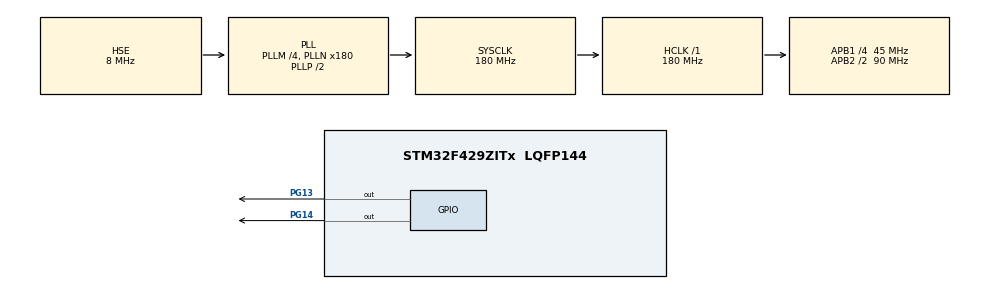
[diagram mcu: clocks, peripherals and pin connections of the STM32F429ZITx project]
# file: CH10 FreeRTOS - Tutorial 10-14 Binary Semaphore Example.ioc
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FREERTOS.Tasks01=defaultTask,24,128,StartDefaultTask,Default,NULL,Dynamic,NULL,NULL
FREERTOS.configUSE_NEWLIB_REENTRANT=1
Mcu.Family=STM32F4
Mcu.Name=STM32F429ZITx
Mcu.Package=LQFP144
NVIC.PriorityGroup=NVIC_PRIORITYGROUP_4
NVIC.TIM6_DAC_IRQn=true\:0\:0\:true\:false\:true\:false\:false\:true\:true
NVIC.TimeBase=TIM6_DAC_IRQn
NVIC.TimeBaseIP=TIM6
PG13.Signal=GPIO_Output
PG14.Signal=GPIO_Output
PH0/OSC_IN.Mode=HSE-External-Oscillator
PH0/OSC_IN.Signal=RCC_OSC_IN
PH1/OSC_OUT.Mode=HSE-External-Oscillator
PH1/OSC_OUT.Signal=RCC_OSC_OUT
ProjectManager.HeapSize=0x200
ProjectManager.StackSize=0x400
ProjectManager.TargetToolchain=STM32CubeIDE
RCC.48MHZClocksFreq_Value=51428571.428571425
RCC.AHBFreq_Value=180000000
RCC.APB1CLKDivider=RCC_HCLK_DIV4
RCC.APB1Freq_Value=45000000
RCC.APB1TimFreq_Value=90000000
RCC.APB2CLKDivider=RCC_HCLK_DIV2
RCC.APB2Freq_Value=90000000
RCC.APB2TimFreq_Value=180000000
RCC.CortexFreq_Value=180000000
RCC.HCLKFreq_Value=180000000
RCC.HSE_VALUE=8000000
RCC.HSI_VALUE=16000000
RCC.LSE_VALUE=32768
RCC.PLLM=4
RCC.PLLN=180
RCC.PLLQ=7
RCC.PLLSourceVirtual=RCC_PLLSOURCE_HSE
RCC.SYSCLKFreq_VALUE=180000000
RCC.SYSCLKSource=RCC_SYSCLKSOURCE_PLLCLK
RCC.VCOOutputFreq_Value=360000000
VP_FREERTOS_VS_CMSIS_V2.Mode=CMSIS_V2
VP_SYS_VS_tim6.Mode=TIM6
board=STM32F429I-DISC1

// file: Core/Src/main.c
/* USER CODE BEGIN Header */
/**
  ******************************************************************************
  * @file           : main.c
  * @brief          : Main program body
  ******************************************************************************
  * @attention
  *
  * Copyright (c) 2024 STMicroelectronics.
  * All rights reserved.
  *
  * This software is licensed under terms that can be found in the LICENSE file
  * in the root directory of this software component.
  * If no LICENSE file comes with this software, it is provided AS-IS.
  *
  ******************************************************************************
  */

	/***************************** Tutorial Tags ******************************
		 FreeRTOS
		 Binary semaphore
		 Task management (priority, state)
		 GPIO output
	 **************************************************************************/

	/* 10.5 Binary semaphore in FreeRTOS: **************************************
	 * Tutorial -10-14: The binary semaphore example in FreeRTOS
	 *
	WARNING: CODE is written mostly without help of CubeMX. If you regenerate code using CubeMX
	you will lose the code here.

    In this tutorial, we repeat the code in tutorial 10.13 now
	using a binary semaphore. When the code is executed, myTask02 is called first since
	it has higher priority. This task calls the function LEDChange and the green LED on
	the STM32F4 board is turned on. After one second, myTask2 yields for 0.5 s. Then,
	the default task is called. This task calls the function LEDChange and the green LED
	is turned off. After 0.5 s, myTask2 becomes ready and tries to preempt. However,
	the binary semaphore token has been acquired by the default task. Hence, myTask2
	waits for extra 0.5 s even if it has higher priority. myTask2 is executed again when
	the default task releases the binary semaphore token. As a result, green LED toggles
	every second.

	***************************************************************************/

/* USER CODE END Header */
#include "main.h"
#include "cmsis_os.h"

/* USER CODE BEGIN Includes */
#include "stdio.h"
/* USER CODE END Includes */

/* Definitions for defaultTask */
osThreadId_t defaultTaskHandle;
const osThreadAttr_t defaultTask_attributes = {
  .name = "defaultTask",
  .stack_size = 128 * 4,
  .priority = (osPriority_t) osPriorityNormal,
};

/*Definition for myTask02*/
/* USER CODE BEGIN PV */
osThreadId_t myTask02Handle;
const osThreadAttr_t myTask02_attributes = {
		.name = "myTask02",
		.stack_size = 128 * 4,
		.priority = (osPriority_t) osPriorityAboveNormal,
};

/*Definition for myTask02*/
osSemaphoreId_t myBinarySem01Handle;

const osSemaphoreAttr_t myBinarySem01_attributes = {
		.name = "myBinarySem01",
};

// LED GPIO PIN state
int condition;

/* USER CODE END PV */

void SystemClock_Config(void);
static void MX_GPIO_Init(void);

void StartDefaultTask(void *argument);
void StartmyTask02(void *argument);

/*Shared function*/
void ledChange(int condition);

/* USER CODE BEGIN 0 */
/*Function needed to use printf on CONSOLE*/
int _write(int file, char *ptr, int len){
	  int i = 0;
	  for (i=0; i<len; i++)
		  ITM_SendChar((*ptr++));
	  return len;
}
/* USER CODE END 0 */

int main(void)
{

  /* MCU Configuration--------------------------------------------------------*/

  /* Reset of all peripherals, Initializes the Flash interface and the Systick. */
  HAL_Init();

  /* Configure the system clock */
  SystemClock_Config();

  /* Initialize all configured peripherals */
  MX_GPIO_Init();
  /* USER CODE BEGIN 2 */
  printf("PROGRAM START \n\r");
  /* USER CODE END 2 */

  /* Init scheduler */
  osKernelInitialize();

  /* USER CODE BEGIN RTOS_SEMAPHORES */
  myBinarySem01Handle = osSemaphoreNew(1, 1, &myBinarySem01_attributes);
  /* USER CODE END RTOS_SEMAPHORES */

  /* Create the thread(s) */
  /* creation of defaultTask */
  defaultTaskHandle = osThreadNew(StartDefaultTask, NULL, &defaultTask_attributes);

  /* USER CODE BEGIN RTOS_THREADS */
  myTask02Handle = osThreadNew(StartmyTask02, NULL, &myTask02_attributes);
  /* USER CODE END RTOS_THREADS */

  /* Start scheduler */
  osKernelStart();

  /* We should never get here as control is now taken by the scheduler */
  /* Infinite loop */
  while (1)
  {

  }
}

void SystemClock_Config(void)
{
  RCC_OscInitTypeDef RCC_OscInitStruct = {0};
  RCC_ClkInitTypeDef RCC_ClkInitStruct = {0};

  /** Configure the main internal regulator output voltage
  */
  __HAL_RCC_PWR_CLK_ENABLE();
  __HAL_PWR_VOLTAGESCALING_CONFIG(PWR_REGULATOR_VOLTAGE_SCALE1);

  /** Initializes the RCC Oscillators according to the specified parameters
  * in the RCC_OscInitTypeDef structure.
  */
  RCC_OscInitStruct.OscillatorType = RCC_OSCILLATORTYPE_HSE;
  RCC_OscInitStruct.HSEState = RCC_HSE_ON;
  RCC_OscInitStruct.PLL.PLLState = RCC_PLL_ON;
  RCC_OscInitStruct.PLL.PLLSource = RCC_PLLSOURCE_HSE;
  RCC_OscInitStruct.PLL.PLLM = 4;
  RCC_OscInitStruct.PLL.PLLN = 180;
  RCC_OscInitStruct.PLL.PLLP = RCC_PLLP_DIV2;
  RCC_OscInitStruct.PLL.PLLQ = 7;
  if (HAL_RCC_OscConfig(&RCC_OscInitStruct) != HAL_OK)
  {
    Error_Handler();
  }

  /** Activate the Over-Drive mode
  */
  if (HAL_PWREx_EnableOverDrive() != HAL_OK)
  {
    Error_Handler();
  }

  /** Initializes the CPU, AHB and APB buses clocks
  */
  RCC_ClkInitStruct.ClockType = RCC_CLOCKTYPE_HCLK|RCC_CLOCKTYPE_SYSCLK
                              |RCC_CLOCKTYPE_PCLK1|RCC_CLOCKTYPE_PCLK2;
  RCC_ClkInitStruct.SYSCLKSource = RCC_SYSCLKSOURCE_PLLCLK;
  RCC_ClkInitStruct.AHBCLKDivider = RCC_SYSCLK_DIV1;
  RCC_ClkInitStruct.APB1CLKDivider = RCC_HCLK_DIV4;
  RCC_ClkInitStruct.APB2CLKDivider = RCC_HCLK_DIV2;

  if (HAL_RCC_ClockConfig(&RCC_ClkInitStruct, FLASH_LATENCY_5) != HAL_OK)
  {
    Error_Handler();
  }
}

static void MX_GPIO_Init(void)
{
  GPIO_InitTypeDef GPIO_InitStruct = {0};

  /* GPIO Ports Clock Enable */
  __HAL_RCC_GPIOH_CLK_ENABLE();
  __HAL_RCC_GPIOG_CLK_ENABLE();

  /*Configure GPIO pin Output Level */
  HAL_GPIO_WritePin(GPIOG, GPIO_PIN_13|GPIO_PIN_14, GPIO_PIN_RESET);

  /*Configure GPIO pins : PG13 PG14 */
  GPIO_InitStruct.Pin = GPIO_PIN_13|GPIO_PIN_14;
  GPIO_InitStruct.Mode = GPIO_MODE_OUTPUT_PP;
  GPIO_InitStruct.Pull = GPIO_NOPULL;
  GPIO_InitStruct.Speed = GPIO_SPEED_FREQ_LOW;
  HAL_GPIO_Init(GPIOG, &GPIO_InitStruct);

}

void StartDefaultTask(void *argument)
{
  /* USER CODE BEGIN 5 */

  /* Infinite loop */
  for(;;)
  {
	  printf("DefaultTask \n\r");
	  ledChange(0);
	  osThreadYield();
  }
  /* USER CODE END 5 */
}

void StartmyTask02(void *argument)
{
  /* USER CODE BEGIN 5 */

  /* Infinite loop */
  for(;;)
  {
	  printf("myTask02 \n");
	  ledChange(1);
	  osDelay(500);
  }
  /* USER CODE END 5 */
}

void ledChange(int condition){
	osSemaphoreAcquire(myBinarySem01Handle, osWaitForever);

	HAL_GPIO_WritePin(GPIOG, GPIO_PIN_13, condition);
	HAL_Delay(1000);

	osSemaphoreRelease(myBinarySem01Handle);
}

void HAL_TIM_PeriodElapsedCallback(TIM_HandleTypeDef *htim)
{
  if (htim->Instance == TIM6) {
    HAL_IncTick();
  }
}

void Error_Handler(void)
{
  __disable_irq();
  while (1)
  {
  }
}
